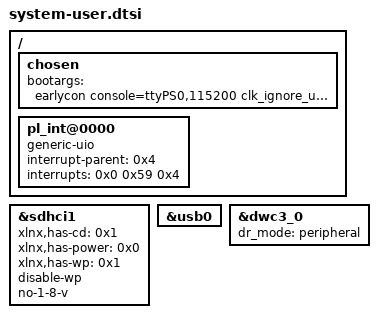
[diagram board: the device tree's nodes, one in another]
/include/ "system-conf.dtsi"
/ {
	chosen {
		bootargs = "earlycon console=ttyPS0,115200 clk_ignore_unused root=/dev/mmcblk1p2 rw rootwait uio_pdrv_genirq.of_id=generic-uio";
	};
	pl_int@0000 {
		compatible = "generic-uio";
		interrupt-parent = <0x4>;
		interrupts = <0x0 0x59 0x4>;
	};
};

&sdhci1 {
	status = "okay";
	xlnx,has-cd = <0x1>;
	xlnx,has-power = <0x0>;
	xlnx,has-wp = <0x1>;
	disable-wp;
	no-1-8-v;
};

&usb0 {
	status = "okay";
};

&dwc3_0 {
	status = "okay";
	dr_mode = "peripheral";
};


